# STM32F411 register map
File version: 1.1
CPU: CM4 r1p0, little endian, no MPU, no FPU, 3 interrupt priority bits
Registers are 32-bit, read-write, reset 0x0 unless marked. A register's access mark holds for its fields unless they carry their own. Offsets are from the block's base; [hi:lo] are bit positions; {n}, {i} and the like mark numbered series; 'fields as' and 'values as' point back to an identical list.

## CRC — Cryptographic processor
Base 0x40023000
0x00 DR reset 0xFFFFFFFF — Data register
  [31:0] DR — Data Register
0x04 IDR — Independent Data register
  [7:0] IDR
0x08 CR wo — Control register
  [0] CR — Control regidter

## DBG — Debug support
Base 0xE0042000
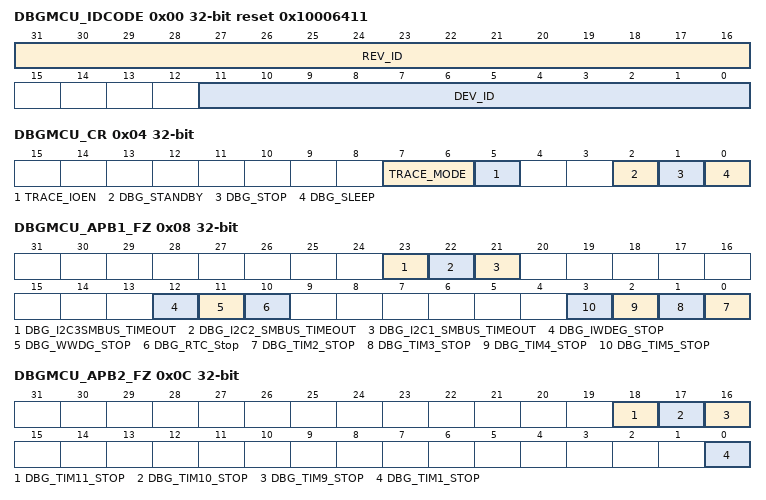
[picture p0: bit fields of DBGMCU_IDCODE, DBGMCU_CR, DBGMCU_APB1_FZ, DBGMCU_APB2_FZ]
0x00 DBGMCU_IDCODE ro reset 0x10006411 — IDCODE
  [31:16] REV_ID, [11:0] DEV_ID
0x04 DBGMCU_CR — Control Register
  [7:6] TRACE_MODE, [5] TRACE_IOEN, [2] DBG_STANDBY, [1] DBG_STOP, [0] DBG_SLEEP
0x08 DBGMCU_APB1_FZ — Debug MCU APB1 Freeze registe
  [23] DBG_I2C3SMBUS_TIMEOUT — DBG_J2C3SMBUS_TIMEOUT
  [22] DBG_I2C2_SMBUS_TIMEOUT — DBG_J2C2_SMBUS_TIMEOUT
  [21] DBG_I2C1_SMBUS_TIMEOUT — DBG_J2C1_SMBUS_TIMEOUT
  [12] DBG_IWDEG_STOP
  [11] DBG_WWDG_STOP
  [10] DBG_RTC_Stop — RTC stopped when Core is halted
  [n-2] DBG_TIM{n}_STOP (n=2..5)
0x0C DBGMCU_APB2_FZ — Debug MCU APB2 Freeze registe
  [18] DBG_TIM11_STOP — TIM11 counter stopped when core is halted
  [17] DBG_TIM10_STOP — TIM10 counter stopped when core is halted
  [16] DBG_TIM9_STOP — TIM9 counter stopped when core is halted
  [0] DBG_TIM1_STOP — TIM1 counter stopped when core is halted

## EXTI — External interrupt/event controller
Base 0x40013C00
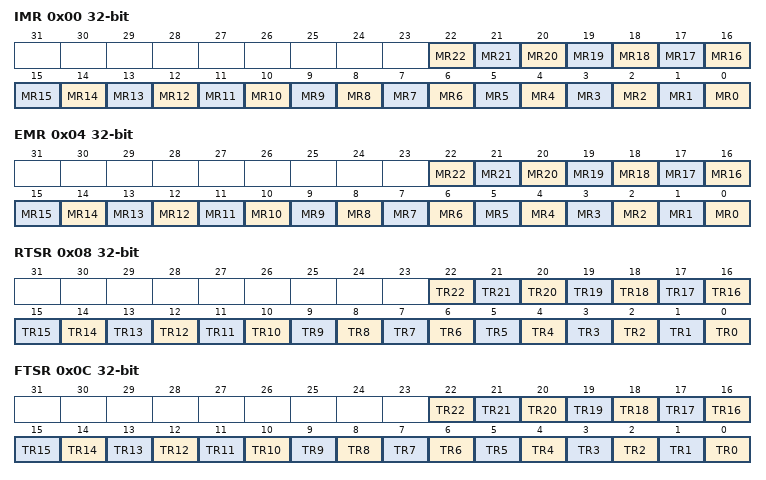
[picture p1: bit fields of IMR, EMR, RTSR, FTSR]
0x00 IMR — Interrupt mask register (EXTI_IMR)
  [n] MR{n} (n=0..22) — Interrupt Mask on line {n}
0x04 EMR — Event mask register (EXTI_EMR)
  [n] MR{n} (n=0..22) — Event Mask on line {n}
0x08 RTSR — Rising Trigger selection register (EXTI_RTSR)
  [n] TR{n} (n=0..22) — Rising trigger event configuration of line {n}
0x0C FTSR — Falling Trigger selection register (EXTI_FTSR)
  [n] TR{n} (n=0..22) — Falling trigger event configuration of line {n}
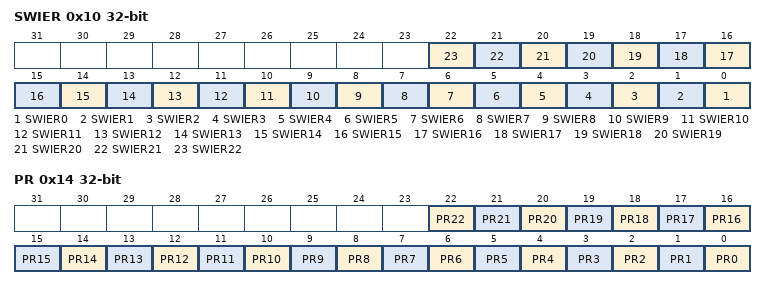
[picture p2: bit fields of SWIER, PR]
0x10 SWIER — Software interrupt event register (EXTI_SWIER)
  [n] SWIER{n} (n=0..22) — Software Interrupt on line {n}
0x14 PR — Pending register (EXTI_PR)
  [n] PR{n} (n=0..22) — Pending bit {n}

## FLASH
Base 0x40023C00
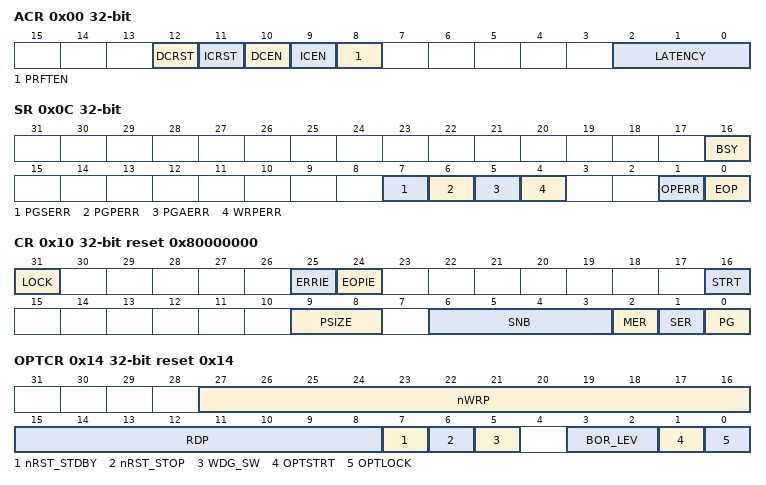
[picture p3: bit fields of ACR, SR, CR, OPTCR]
0x00 ACR access per field — Flash access control register
  [12] DCRST rw — Data cache reset
  [11] ICRST wo — Instruction cache reset
  [10] DCEN rw — Data cache enable
  [9] ICEN rw — Instruction cache enable
  [8] PRFTEN rw — Prefetch enable
  [2:0] LATENCY rw
0x04 KEYR wo — Flash key register
  [31:0] KEY — FPEC key
0x08 OPTKEYR wo — Flash option key register
  [31:0] OPTKEY — Option byte key
0x0C SR access per field — Status register
  [16] BSY ro — Busy
  [7] PGSERR rw — Programming sequence error
  [6] PGPERR rw — Programming parallelism error
  [5] PGAERR rw — Programming alignment error
  [4] WRPERR rw — Write protection error
  [1] OPERR rw — Operation error
  [0] EOP rw — End of operation
0x10 CR reset 0x80000000 — Control register
  [31] LOCK
  [25] ERRIE — Error interrupt enable
  [24] EOPIE — End of operation interrupt enable
  [16] STRT — Start
  [9:8] PSIZE — Program size
  [6:3] SNB — Sector number
  [2] MER — Mass Erase
  [1] SER — Sector Erase
  [0] PG — Programming
0x14 OPTCR reset 0x14 — Flash option control register
  [27:16] nWRP — Not write protect
  [15:8] RDP — Read protect
  [7] nRST_STDBY — nRST_STDBY User option bytes
  [6] nRST_STOP — nRST_STOP User option bytes
  [5] WDG_SW — WDG_SW User option bytes
  [3:2] BOR_LEV — BOR reset Level
  [1] OPTSTRT — Option start
  [0] OPTLOCK — Option lock

## IWDG — Independent watchdog
Base 0x40003000
0x00 KR wo — Key register
  [15:0] KEY — Key value
0x04 PR — Prescaler register
  [2:0] PR — Prescaler divider
0x08 RLR reset 0xFFF — Reload register
  [11:0] RL — Watchdog counter reload value
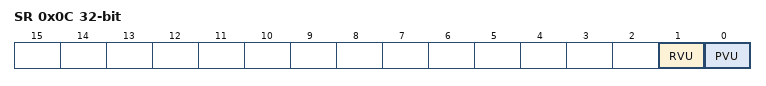
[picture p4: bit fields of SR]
0x0C SR ro — Status register
  [1] RVU — Watchdog counter reload value update
  [0] PVU — Watchdog prescaler value update

## OTG_FS_HOST — USB on the go full speed
Base 0x50000400
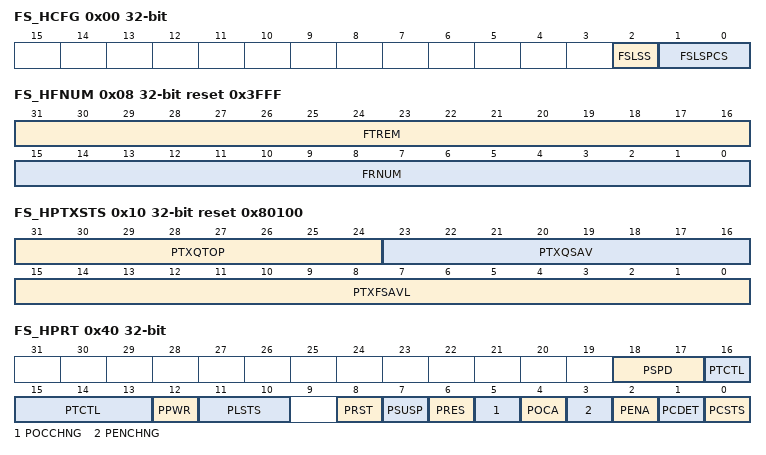
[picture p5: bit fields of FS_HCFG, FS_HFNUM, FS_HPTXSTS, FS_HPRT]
0x00 FS_HCFG access per field — OTG_FS host configuration register (OTG_FS_HCFG)
  [2] FSLSS ro — FS- and LS-only support
  [1:0] FSLSPCS rw — FS/LS PHY clock select
0x04 HFIR reset 0xEA60 — OTG_FS Host frame interval register
  [15:0] FRIVL — Frame interval
0x08 FS_HFNUM ro reset 0x3FFF — OTG_FS host frame number/frame time remaining register (OTG_FS_HFNUM)
  [31:16] FTREM — Frame time remaining
  [15:0] FRNUM — Frame number
0x10 FS_HPTXSTS access per field reset 0x80100 — OTG_FS_Host periodic transmit FIFO/queue status register (OTG_FS_HPTXSTS)
  [31:24] PTXQTOP ro — Top of the periodic transmit request queue
  [23:16] PTXQSAV ro — Periodic transmit request queue space available
  [15:0] PTXFSAVL rw — Periodic transmit data FIFO space available
0x14 HAINT ro — OTG_FS Host all channels interrupt register
  [15:0] HAINT — Channel interrupts
0x18 HAINTMSK — OTG_FS host all channels interrupt mask register
  [15:0] HAINTM — Channel interrupt mask
0x40 FS_HPRT access per field — OTG_FS host port control and status register (OTG_FS_HPRT)
  [18:17] PSPD ro — Port speed
  [16:13] PTCTL rw — Port test control
  [12] PPWR rw — Port power
  [11:10] PLSTS ro — Port line status
  [8] PRST rw — Port reset
  [7] PSUSP rw — Port suspend
  [6] PRES rw — Port resume
  [5] POCCHNG rw — Port overcurrent change
  [4] POCA ro — Port overcurrent active
  [3] PENCHNG rw — Port enable/disable change
  [2] PENA rw — Port enable
  [1] PCDET rw — Port connect detected
  [0] PCSTS ro — Port connect status
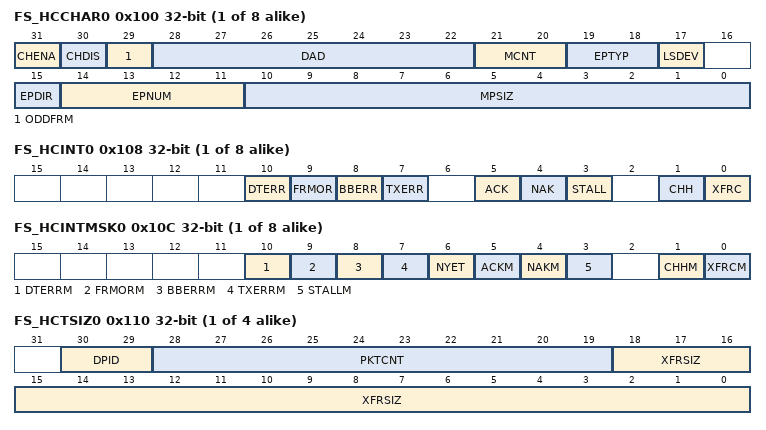
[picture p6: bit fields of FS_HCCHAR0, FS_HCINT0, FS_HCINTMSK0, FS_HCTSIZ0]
{0x100+0x20*i} FS_HCCHAR{i} (i=0..7) — OTG_FS host channel-{i} characteristics register (OTG_FS_HCCHAR{i})
  [31] CHENA — Channel enable
  [30] CHDIS — Channel disable
  [29] ODDFRM — Odd frame
  [28:22] DAD — Device address
  [21:20] MCNT — Multicount
  [19:18] EPTYP — Endpoint type
  [17] LSDEV — Low-speed device
  [15] EPDIR — Endpoint direction
  [14:11] EPNUM — Endpoint number
  [10:0] MPSIZ — Maximum packet size
{0x108+0x20*i} FS_HCINT{i} (i=0..7) — OTG_FS host channel-{i} interrupt register (OTG_FS_HCINT{i})
  [10] DTERR — Data toggle error
  [9] FRMOR — Frame overrun
  [8] BBERR — Babble error
  [7] TXERR — Transaction error
  [5] ACK — ACK response received/transmitted interrupt
  [4] NAK — NAK response received interrupt
  [3] STALL — STALL response received interrupt
  [1] CHH — Channel halted
  [0] XFRC — Transfer completed
{0x10C+0x20*i} FS_HCINTMSK{i} (i=0..7) — OTG_FS host channel-{i} mask register (OTG_FS_HCINTMSK{i})
  [10] DTERRM — Data toggle error mask
  [9] FRMORM — Frame overrun mask
  [8] BBERRM — Babble error mask
  [7] TXERRM — Transaction error mask
  [6] NYET — response received interrupt mask
  [5] ACKM — ACK response received/transmitted interrupt mask
  [4] NAKM — NAK response received interrupt mask
  [3] STALLM — STALL response received interrupt mask
  [1] CHHM — Channel halted mask
  [0] XFRCM — Transfer completed mask
{0x110+0x20*i} FS_HCTSIZ{i} (i=0..3) — OTG_FS host channel-{i} transfer size register
  [30:29] DPID — Data PID
  [28:19] PKTCNT — Packet count
  [18:0] XFRSIZ — Transfer size
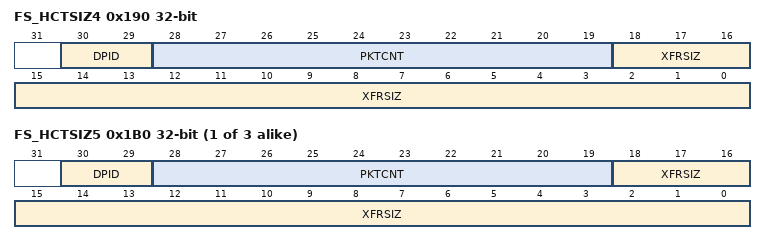
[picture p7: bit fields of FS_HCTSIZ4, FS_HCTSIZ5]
0x190 FS_HCTSIZ4 — OTG_FS host channel-x transfer size register
  fields as FS_HCTSIZ0
{0x110+0x20*i} FS_HCTSIZ{i} (i=5..7) — OTG_FS host channel-{i} transfer size register
  fields as FS_HCTSIZ0
